VERSION ""

NS_ :

BS_:

BU_:

BO_ 336 HEARTBEAT: 8 Vector__XXX
 SG_ State : 0|8@1+ (1,0) [0|0] "" Vector__XXX
 SG_ Counter : 8|8@1+ (1,0) [0|0] "" Vector__XXX

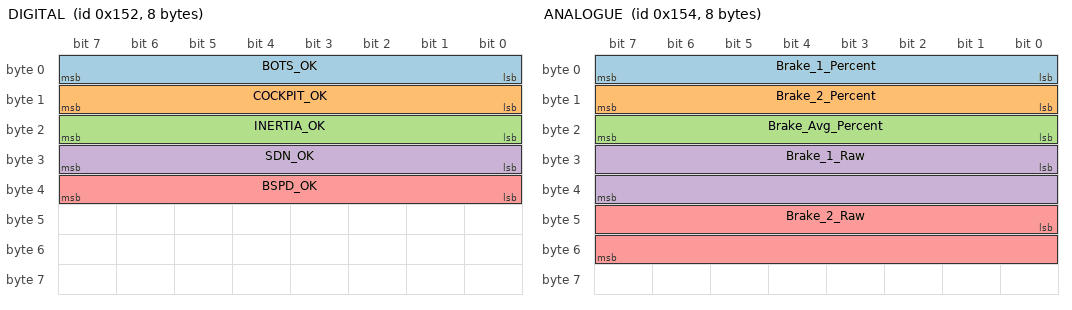
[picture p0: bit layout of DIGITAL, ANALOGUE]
BO_ 338 DIGITAL: 8 Vector__XXX
 SG_ BOTS_OK : 0|8@1+ (1,0) [0|0] "" Vector__XXX
 SG_ COCKPIT_OK : 8|8@1+ (1,0) [0|0] "" Vector__XXX
 SG_ INERTIA_OK : 16|8@1+ (1,0) [0|0] "" Vector__XXX
 SG_ SDN_OK : 24|8@1+ (1,0) [0|0] "" Vector__XXX
 SG_ BSPD_OK : 32|8@1+ (1,0) [0|0] "" Vector__XXX

BO_ 340 ANALOGUE: 8 Vector__XXX
 SG_ Brake_1_Percent : 0|8@1+ (1,0) [0|0] "%" Vector__XXX
 SG_ Brake_2_Percent : 8|8@1+ (1,0) [0|0] "%" Vector__XXX
 SG_ Brake_Avg_Percent : 16|8@1+ (1,0) [0|0] "%" Vector__XXX
 SG_ Brake_1_Raw : 24|16@1+ (1,0) [0|0] "" Vector__XXX
 SG_ Brake_2_Raw : 40|16@1+ (1,0) [0|0] "" Vector__XXX
